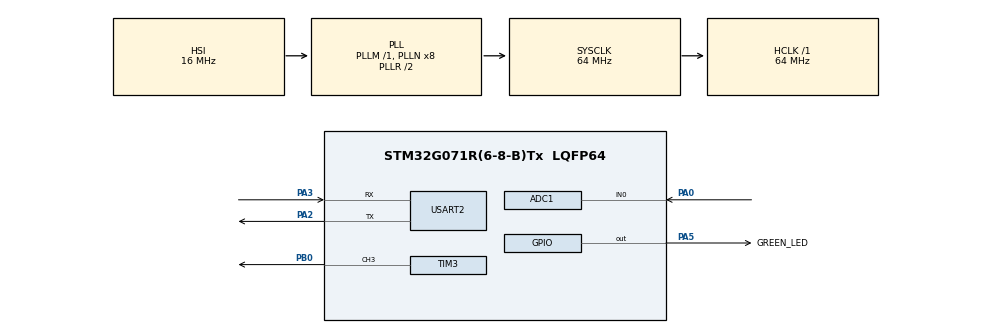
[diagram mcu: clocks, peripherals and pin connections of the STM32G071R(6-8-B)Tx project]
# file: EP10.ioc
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ADC1.Channel-0\#ChannelRegularConversion=ADC_CHANNEL_0
ADC1.ContinuousConvMode=ENABLE
ADC1.NbrOfConversionFlag=1
ADC1.Rank-0\#ChannelRegularConversion=1
ADC1.SamplingTime-0\#ChannelRegularConversion=ADC_SAMPLINGTIME_COMMON_1
ADC1.SamplingTimeCommon1=ADC_SAMPLETIME_12CYCLES_5
ADC1.SelectedChannel=ADC_CHANNEL_0
ADC1.master=1
Mcu.Family=STM32G0
Mcu.Name=STM32G071R(6-8-B)Tx
Mcu.Package=LQFP64
PA0.Mode=IN0
PA0.Signal=ADC1_IN0
PA2.Mode=Asynchronous
PA2.Signal=USART2_TX
PA3.Mode=Asynchronous
PA3.Signal=USART2_RX
PA5.GPIO_Label=GREEN_LED
PA5.Signal=GPIO_Output
PB0.Signal=S_TIM3_CH3
ProjectManager.HeapSize=0x200
ProjectManager.StackSize=0x400
ProjectManager.TargetToolchain=STM32CubeIDE
RCC.ADCFreq_Value=64000000
RCC.AHBFreq_Value=64000000
RCC.CortexFreq_Value=64000000
RCC.EXTERNAL_CLOCK_VALUE=48000
RCC.HCLKFreq_Value=64000000
RCC.HSE_VALUE=8000000
RCC.HSI_VALUE=16000000
RCC.LSE_VALUE=32768
RCC.SYSCLKFreq_VALUE=64000000
RCC.SYSCLKSource=RCC_SYSCLKSOURCE_PLLCLK
RCC.VCOOutputFreq_Value=128000000
SH.S_TIM3_CH3.0=TIM3_CH3,PWM Generation3 CH3
TIM3.Channel-PWM\ Generation3\ CH3=TIM_CHANNEL_3
TIM3.Period=9999
TIM3.Prescaler=63
USART2.VirtualMode-Asynchronous=VM_ASYNC
VP_TIM3_VS_ClockSourceINT.Mode=Internal
board=custom

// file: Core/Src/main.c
/* USER CODE BEGIN Header */
/**
  ******************************************************************************
  * @file           : main.c
  * @brief          : Main program body
  ******************************************************************************
  * @attention
  *
  * Copyright (c) 2025 STMicroelectronics.
  * All rights reserved.
  *
  * This software is licensed under terms that can be found in the LICENSE file
  * in the root directory of this software component.
  * If no LICENSE file comes with this software, it is provided AS-IS.
  *
  ******************************************************************************
  */
/* USER CODE END Header */
#include "main.h"
#include "adc.h"
#include "tim.h"
#include "usart.h"
#include "gpio.h"

/* USER CODE BEGIN PV */
uint32_t adcValue = 0;
uint32_t pwmValue = 0;
/* USER CODE END PV */

void SystemClock_Config(void);

int main(void)
{

  /* MCU Configuration--------------------------------------------------------*/

  /* Reset of all peripherals, Initializes the Flash interface and the Systick. */
  HAL_Init();

  /* Configure the system clock */
  SystemClock_Config();

  /* Initialize all configured peripherals */
  MX_GPIO_Init();
  MX_ADC1_Init();
  MX_TIM3_Init();
  MX_USART2_UART_Init();
  /* USER CODE BEGIN 2 */
  HAL_ADCEx_Calibration_Start(&hadc1);
  HAL_ADC_Start(&hadc1);

  HAL_TIM_PWM_Start(&htim3, TIM_CHANNEL_3);
  /* USER CODE END 2 */

  /* Infinite loop */
  while (1)
  {

    /* USER CODE BEGIN 3 */
	  if(HAL_ADC_PollForConversion(&hadc1, 100) == HAL_OK)
	  {
		  adcValue = HAL_ADC_GetValue(&hadc1);
		  pwmValue = (adcValue * 9999) / 4095;
		  __HAL_TIM_SET_COMPARE(&htim3, TIM_CHANNEL_3, pwmValue);
	  }
  }
  /* USER CODE END 3 */
}

void SystemClock_Config(void)
{
  RCC_OscInitTypeDef RCC_OscInitStruct = {0};
  RCC_ClkInitTypeDef RCC_ClkInitStruct = {0};

  /** Configure the main internal regulator output voltage
  */
  HAL_PWREx_ControlVoltageScaling(PWR_REGULATOR_VOLTAGE_SCALE1);

  /** Initializes the RCC Oscillators according to the specified parameters
  * in the RCC_OscInitTypeDef structure.
  */
  RCC_OscInitStruct.OscillatorType = RCC_OSCILLATORTYPE_HSI;
  RCC_OscInitStruct.HSIState = RCC_HSI_ON;
  RCC_OscInitStruct.HSIDiv = RCC_HSI_DIV1;
  RCC_OscInitStruct.HSICalibrationValue = RCC_HSICALIBRATION_DEFAULT;
  RCC_OscInitStruct.PLL.PLLState = RCC_PLL_ON;
  RCC_OscInitStruct.PLL.PLLSource = RCC_PLLSOURCE_HSI;
  RCC_OscInitStruct.PLL.PLLM = RCC_PLLM_DIV1;
  RCC_OscInitStruct.PLL.PLLN = 8;
  RCC_OscInitStruct.PLL.PLLP = RCC_PLLP_DIV2;
  RCC_OscInitStruct.PLL.PLLQ = RCC_PLLQ_DIV2;
  RCC_OscInitStruct.PLL.PLLR = RCC_PLLR_DIV2;
  if (HAL_RCC_OscConfig(&RCC_OscInitStruct) != HAL_OK)
  {
    Error_Handler();
  }

  /** Initializes the CPU, AHB and APB buses clocks
  */
  RCC_ClkInitStruct.ClockType = RCC_CLOCKTYPE_HCLK|RCC_CLOCKTYPE_SYSCLK
                              |RCC_CLOCKTYPE_PCLK1;
  RCC_ClkInitStruct.SYSCLKSource = RCC_SYSCLKSOURCE_PLLCLK;
  RCC_ClkInitStruct.AHBCLKDivider = RCC_SYSCLK_DIV1;
  RCC_ClkInitStruct.APB1CLKDivider = RCC_HCLK_DIV1;

  if (HAL_RCC_ClockConfig(&RCC_ClkInitStruct, FLASH_LATENCY_2) != HAL_OK)
  {
    Error_Handler();
  }
}

void Error_Handler(void)
{
  __disable_irq();
  while (1)
  {
  }
}
